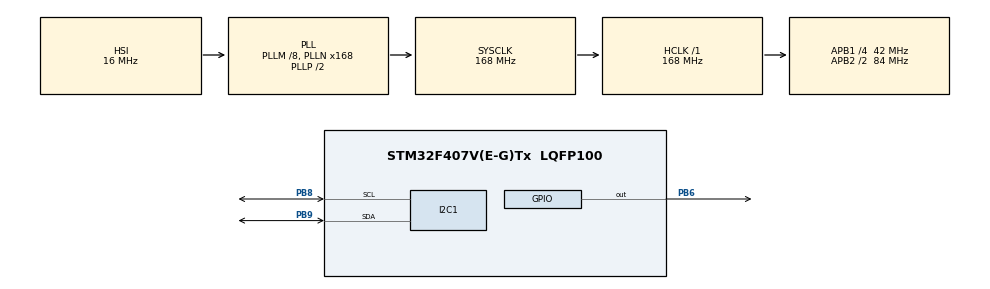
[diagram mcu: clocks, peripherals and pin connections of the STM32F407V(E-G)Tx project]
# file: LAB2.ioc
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I2C1.I2C_Mode=I2C_Fast
Mcu.Family=STM32F4
Mcu.Name=STM32F407V(E-G)Tx
Mcu.Package=LQFP100
NVIC.PriorityGroup=NVIC_PRIORITYGROUP_4
PA13.Mode=Serial_Wire
PA13.Signal=SYS_JTMS-SWDIO
PA14.Mode=Serial_Wire
PA14.Signal=SYS_JTCK-SWCLK
PB6.Signal=GPIO_Output
PB8.Mode=I2C
PB8.Signal=I2C1_SCL
PB9.Mode=I2C
PB9.Signal=I2C1_SDA
PH0-OSC_IN.Mode=HSE-External-Oscillator
PH0-OSC_IN.Signal=RCC_OSC_IN
PH1-OSC_OUT.Mode=HSE-External-Oscillator
PH1-OSC_OUT.Signal=RCC_OSC_OUT
ProjectManager.HeapSize=0x200
ProjectManager.StackSize=0x400
ProjectManager.TargetToolchain=STM32CubeIDE
RCC.48MHZClocksFreq_Value=84000000
RCC.AHBFreq_Value=168000000
RCC.APB1CLKDivider=RCC_HCLK_DIV4
RCC.APB1Freq_Value=42000000
RCC.APB1TimFreq_Value=84000000
RCC.APB2CLKDivider=RCC_HCLK_DIV2
RCC.APB2Freq_Value=84000000
RCC.APB2TimFreq_Value=168000000
RCC.CortexFreq_Value=168000000
RCC.HCLKFreq_Value=168000000
RCC.HSE_VALUE=25000000
RCC.HSI_VALUE=16000000
RCC.LSE_VALUE=32768
RCC.PLLM=8
RCC.PLLN=168
RCC.SYSCLKFreq_VALUE=168000000
RCC.SYSCLKSource=RCC_SYSCLKSOURCE_PLLCLK
RCC.VCOOutputFreq_Value=336000000
TIM1.Prescaler=167
VP_TIM1_VS_ClockSourceINT.Mode=Internal
board=custom

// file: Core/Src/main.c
/* USER CODE BEGIN Header */
/**
  ******************************************************************************
  * @file           : main.c
  * @brief          : Main program body
  ******************************************************************************
  * @attention
  *
  * Copyright (c) 2024 STMicroelectronics.
  * All rights reserved.
  *
  * This software is licensed under terms that can be found in the LICENSE file
  * in the root directory of this software component.
  * If no LICENSE file comes with this software, it is provided AS-IS.
  *
  ******************************************************************************
  */
/* USER CODE END Header */
#include <lcd_i2c_lib.h>
#include "main.h"
#include <stdbool.h>
#include <stdio.h>

I2C_HandleTypeDef hi2c1;

TIM_HandleTypeDef htim1;

void SystemClock_Config(void);
static void MX_GPIO_Init(void);
static void MX_I2C1_Init(void);
static void MX_TIM1_Init(void);

/* USER CODE BEGIN 0 */
#define DHT11_PORT GPIOB
#define DHT11_PIN GPIO_PIN_6
uint8_t RHI, RHD, TCI, TCD, SUM;
uint32_t pMillis, cMillis;
char strCopy[40];

void microDelay (uint16_t delay)
{
  __HAL_TIM_SET_COUNTER(&htim1, 0);
  while (__HAL_TIM_GET_COUNTER(&htim1) < delay);
}

uint8_t DHT11_Start (void)
{
  uint8_t Response = 0;
  GPIO_InitTypeDef GPIO_InitStructPrivate = {0};
  GPIO_InitStructPrivate.Pin = DHT11_PIN;
  GPIO_InitStructPrivate.Mode = GPIO_MODE_OUTPUT_PP;
  GPIO_InitStructPrivate.Speed = GPIO_SPEED_FREQ_LOW;
  GPIO_InitStructPrivate.Pull = GPIO_NOPULL;
  HAL_GPIO_Init(DHT11_PORT, &GPIO_InitStructPrivate); // set the pin as output
  HAL_GPIO_WritePin (DHT11_PORT, DHT11_PIN, 0);   // pull the pin low
  HAL_Delay(20);   // wait for 20ms
  HAL_GPIO_WritePin (DHT11_PORT, DHT11_PIN, 1);   // pull the pin high
  microDelay (30);   // wait for 30us
  GPIO_InitStructPrivate.Mode = GPIO_MODE_INPUT;
  GPIO_InitStructPrivate.Pull = GPIO_PULLUP;
  HAL_GPIO_Init(DHT11_PORT, &GPIO_InitStructPrivate); // set the pin as input
  microDelay (40);
  if (!(HAL_GPIO_ReadPin (DHT11_PORT, DHT11_PIN)))
  {
    microDelay (80);
    if ((HAL_GPIO_ReadPin (DHT11_PORT, DHT11_PIN))) Response = 1;
  }
  pMillis = HAL_GetTick();
  cMillis = HAL_GetTick();
  while ((HAL_GPIO_ReadPin (DHT11_PORT, DHT11_PIN)) && pMillis + 2 > cMillis)
  {
    cMillis = HAL_GetTick();
  }
  return Response;
}

uint8_t DHT11_Read (void)
{
  uint8_t a,b;
  for (a=0;a<8;a++)
  {
    pMillis = HAL_GetTick();
    cMillis = HAL_GetTick();
    while (!(HAL_GPIO_ReadPin (DHT11_PORT, DHT11_PIN)) && pMillis + 2 > cMillis)
    {  // wait for the pin to go high
      cMillis = HAL_GetTick();
    }
    microDelay (40);   // wait for 40 us
    if (!(HAL_GPIO_ReadPin (DHT11_PORT, DHT11_PIN)))   // if the pin is low
      b&= ~(1<<(7-a));
    else
      b|= (1<<(7-a));
    pMillis = HAL_GetTick();
    cMillis = HAL_GetTick();
    while ((HAL_GPIO_ReadPin (DHT11_PORT, DHT11_PIN)) && pMillis + 2 > cMillis)
    {  // wait for the pin to go low
      cMillis = HAL_GetTick();
    }
  }
  return b;
}
/* USER CODE END 0 */

int main(void)
{

  /* MCU Configuration--------------------------------------------------------*/

  /* Reset of all peripherals, Initializes the Flash interface and the Systick. */
  HAL_Init();

  /* Configure the system clock */
  SystemClock_Config();

  /* Initialize all configured peripherals */
  MX_GPIO_Init();
  MX_I2C1_Init();
  MX_TIM1_Init();
  /* USER CODE BEGIN 2 */
  HAL_Delay(100);
  HAL_TIM_Base_Start(&htim1);
  lcd_Init();
  /* USER CODE END 2 */

  /* Infinite loop */
  /* USER CODE BEGIN WHILE */
  while (1)
  {
	  if(DHT11_Start())
		{
			RHI = DHT11_Read(); // Relative humidity integral
			RHD = DHT11_Read(); // Relative humidity decimal
			TCI = DHT11_Read(); // Celsius integral
			TCD = DHT11_Read(); // Celsius decimal
			SUM = DHT11_Read(); // Check sum
			if (RHI + RHD + TCI + TCD == SUM)
				{
				sprintf(strCopy,"%d.%d C   ", TCI, TCD);
				lcd_SetCursor(0, 0);
				lcd_Print_text(strCopy);
				sprintf(strCopy,"%d.%d %%  ", RHI, RHD);
				lcd_SetCursor(0, 1);
				lcd_Print_text(strCopy);
				}
		}
	  HAL_Delay(2000);
    /* USER CODE END WHILE */

  }
}

void SystemClock_Config(void)
{
  RCC_OscInitTypeDef RCC_OscInitStruct = {0};
  RCC_ClkInitTypeDef RCC_ClkInitStruct = {0};

  /** Configure the main internal regulator output voltage
  */
  __HAL_RCC_PWR_CLK_ENABLE();
  __HAL_PWR_VOLTAGESCALING_CONFIG(PWR_REGULATOR_VOLTAGE_SCALE1);

  /** Initializes the RCC Oscillators according to the specified parameters
  * in the RCC_OscInitTypeDef structure.
  */
  RCC_OscInitStruct.OscillatorType = RCC_OSCILLATORTYPE_HSI;
  RCC_OscInitStruct.HSIState = RCC_HSI_ON;
  RCC_OscInitStruct.HSICalibrationValue = RCC_HSICALIBRATION_DEFAULT;
  RCC_OscInitStruct.PLL.PLLState = RCC_PLL_ON;
  RCC_OscInitStruct.PLL.PLLSource = RCC_PLLSOURCE_HSI;
  RCC_OscInitStruct.PLL.PLLM = 8;
  RCC_OscInitStruct.PLL.PLLN = 168;
  RCC_OscInitStruct.PLL.PLLP = RCC_PLLP_DIV2;
  RCC_OscInitStruct.PLL.PLLQ = 4;
  if (HAL_RCC_OscConfig(&RCC_OscInitStruct) != HAL_OK)
  {
    Error_Handler();
  }

  /** Initializes the CPU, AHB and APB buses clocks
  */
  RCC_ClkInitStruct.ClockType = RCC_CLOCKTYPE_HCLK|RCC_CLOCKTYPE_SYSCLK
                              |RCC_CLOCKTYPE_PCLK1|RCC_CLOCKTYPE_PCLK2;
  RCC_ClkInitStruct.SYSCLKSource = RCC_SYSCLKSOURCE_PLLCLK;
  RCC_ClkInitStruct.AHBCLKDivider = RCC_SYSCLK_DIV1;
  RCC_ClkInitStruct.APB1CLKDivider = RCC_HCLK_DIV4;
  RCC_ClkInitStruct.APB2CLKDivider = RCC_HCLK_DIV2;

  if (HAL_RCC_ClockConfig(&RCC_ClkInitStruct, FLASH_LATENCY_5) != HAL_OK)
  {
    Error_Handler();
  }
}

static void MX_I2C1_Init(void)
{

  hi2c1.Instance = I2C1;
  hi2c1.Init.ClockSpeed = 400000;
  hi2c1.Init.DutyCycle = I2C_DUTYCYCLE_2;
  hi2c1.Init.OwnAddress1 = 0;
  hi2c1.Init.AddressingMode = I2C_ADDRESSINGMODE_7BIT;
  hi2c1.Init.DualAddressMode = I2C_DUALADDRESS_DISABLE;
  hi2c1.Init.OwnAddress2 = 0;
  hi2c1.Init.GeneralCallMode = I2C_GENERALCALL_DISABLE;
  hi2c1.Init.NoStretchMode = I2C_NOSTRETCH_DISABLE;
  if (HAL_I2C_Init(&hi2c1) != HAL_OK)
  {
    Error_Handler();
  }

}

static void MX_TIM1_Init(void)
{

  TIM_ClockConfigTypeDef sClockSourceConfig = {0};
  TIM_MasterConfigTypeDef sMasterConfig = {0};

  htim1.Instance = TIM1;
  htim1.Init.Prescaler = 167;
  htim1.Init.CounterMode = TIM_COUNTERMODE_UP;
  htim1.Init.Period = 65535;
  htim1.Init.ClockDivision = TIM_CLOCKDIVISION_DIV1;
  htim1.Init.RepetitionCounter = 0;
  htim1.Init.AutoReloadPreload = TIM_AUTORELOAD_PRELOAD_DISABLE;
  if (HAL_TIM_Base_Init(&htim1) != HAL_OK)
  {
    Error_Handler();
  }
  sClockSourceConfig.ClockSource = TIM_CLOCKSOURCE_INTERNAL;
  if (HAL_TIM_ConfigClockSource(&htim1, &sClockSourceConfig) != HAL_OK)
  {
    Error_Handler();
  }
  sMasterConfig.MasterOutputTrigger = TIM_TRGO_RESET;
  sMasterConfig.MasterSlaveMode = TIM_MASTERSLAVEMODE_DISABLE;
  if (HAL_TIMEx_MasterConfigSynchronization(&htim1, &sMasterConfig) != HAL_OK)
  {
    Error_Handler();
  }

}

static void MX_GPIO_Init(void)
{
  GPIO_InitTypeDef GPIO_InitStruct = {0};

  /* GPIO Ports Clock Enable */
  __HAL_RCC_GPIOH_CLK_ENABLE();
  __HAL_RCC_GPIOA_CLK_ENABLE();
  __HAL_RCC_GPIOB_CLK_ENABLE();

  /*Configure GPIO pin Output Level */
  HAL_GPIO_WritePin(GPIOB, GPIO_PIN_6, GPIO_PIN_RESET);

  /*Configure GPIO pin : PB6 */
  GPIO_InitStruct.Pin = GPIO_PIN_6;
  GPIO_InitStruct.Mode = GPIO_MODE_OUTPUT_PP;
  GPIO_InitStruct.Pull = GPIO_NOPULL;
  GPIO_InitStruct.Speed = GPIO_SPEED_FREQ_LOW;
  HAL_GPIO_Init(GPIOB, &GPIO_InitStruct);

}

void Error_Handler(void)
{
  __disable_irq();
  while (1)
  {
  }
}
